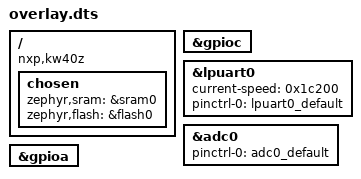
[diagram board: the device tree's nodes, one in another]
/ {
	compatible = "nxp,kw40z", "nxp,mkw40z4";
	chosen {
		zephyr,sram = &sram0;
		zephyr,flash = &flash0;
	};
};
&gpioc{
	status = "okay";
};
&lpuart0{
	status = "okay";
	current-speed = < 0x1c200 >;
	pinctrl-0 = < &lpuart0_default >;
	pinctrl-names = "default";
};
&adc0{
	status = "okay";
	pinctrl-0 = < &adc0_default >;
	pinctrl-names = "default";
};
&gpioa{
	status = "okay";
};
